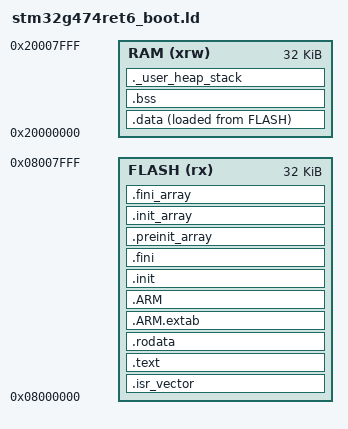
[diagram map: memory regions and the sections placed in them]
/* ============================================================================
 * Bootloader 链接脚本（0x08000000，32KB）
 * RAM 只用 SRAM1 前 32KB（0x20000000-0x20007FFF）：跳转后由 app 重新初始化
 * ==========================================================================*/

ENTRY(Reset_Handler)

_estack = ORIGIN(RAM) + LENGTH(RAM);
_Min_Heap_Size = 0x100;
_Min_Stack_Size = 0x800; /* 2KB 足够 bootloader 使用 */

MEMORY
{
  FLASH (rx)  : ORIGIN = 0x08000000, LENGTH = 32K
  RAM   (xrw) : ORIGIN = 0x20000000, LENGTH = 32K
}

SECTIONS
{
  .isr_vector :
  {
    . = ALIGN(4);
    KEEP(*(.isr_vector))
    . = ALIGN(4);
  } >FLASH

  .text :
  {
    . = ALIGN(4);
    *(.text)
    *(.text*)
    . = ALIGN(4);
  } >FLASH

  .rodata :
  {
    . = ALIGN(4);
    *(.rodata)
    *(.rodata*)
    . = ALIGN(4);
  } >FLASH

  .ARM.extab : { *(.ARM.extab* .gnu.linkonce.armextab.*) } >FLASH
  .ARM : { __exidx_start = .; *(.ARM.exidx*) __exidx_end = .; } >FLASH

  /* KEEP 防止 --gc-sections 裁掉 crtn.o 的 .init/.fini 结尾（否则 _init 不完整会崩） */
  .init :
  {
    KEEP (*(.init))
  } >FLASH

  .fini :
  {
    KEEP (*(.fini))
  } >FLASH

  .preinit_array :
  {
    PROVIDE_HIDDEN(__preinit_array_start = .);
    KEEP(*(.preinit_array*))
    PROVIDE_HIDDEN(__preinit_array_end = .);
  } >FLASH

  .init_array :
  {
    PROVIDE_HIDDEN(__init_array_start = .);
    KEEP(*(SORT(.init_array.*)))
    KEEP(*(.init_array*))
    PROVIDE_HIDDEN(__init_array_end = .);
  } >FLASH

  .fini_array :
  {
    PROVIDE_HIDDEN(__fini_array_start = .);
    KEEP(*(SORT(.fini_array.*)))
    KEEP(*(.fini_array*))
    PROVIDE_HIDDEN(__fini_array_end = .);
  } >FLASH

  _etext = .;
  _sidata = _etext;

  .data :
  {
    . = ALIGN(4);
    _sdata = .;
    __data_start__ = .;
    *(.data)
    *(.data*)
    . = ALIGN(4);
    _edata = .;
    __data_end__ = .;
  } >RAM AT> FLASH

  .bss :
  {
    . = ALIGN(4);
    _sbss = .;
    __bss_start__ = .;
    *(.bss)
    *(.bss*)
    *(COMMON)
    . = ALIGN(4);
    _ebss = .;
    __bss_end__ = .;
  } >RAM

  ._user_heap_stack :
  {
    . = ALIGN(8);
    PROVIDE(end = .);
    PROVIDE(_end = .);
    . = . + _Min_Heap_Size;
    . = . + _Min_Stack_Size;
    . = ALIGN(8);
  } >RAM

  /DISCARD/ :
  {
    libc.a(*)
    libm.a(*)
    libgcc.a(*)
  }
}
